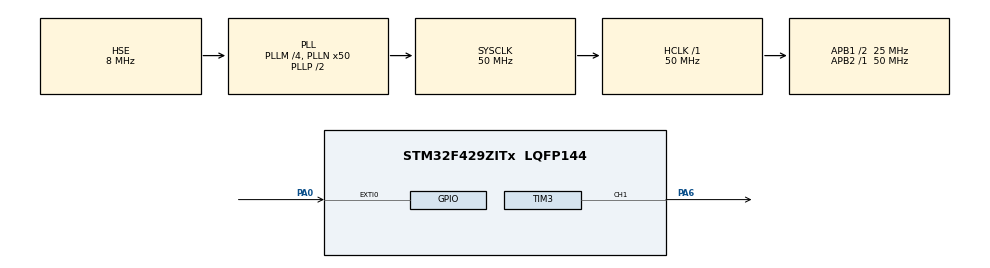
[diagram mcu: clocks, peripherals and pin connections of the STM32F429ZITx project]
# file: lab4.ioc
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Mcu.Family=STM32F4
Mcu.Name=STM32F429ZITx
Mcu.Package=LQFP144
NVIC.EXTI0_IRQn=true\:0\:0\:false\:false\:true\:true\:true\:true
NVIC.PriorityGroup=NVIC_PRIORITYGROUP_4
PA0/WKUP.GPIO_ModeDefaultEXTI=GPIO_MODE_IT_RISING
PA0/WKUP.Signal=GPXTI0
PA13.Mode=Serial_Wire
PA13.Signal=SYS_JTMS-SWDIO
PA14.Mode=Serial_Wire
PA14.Signal=SYS_JTCK-SWCLK
PA6.Signal=S_TIM3_CH1
PH0/OSC_IN.Mode=HSE-External-Oscillator
PH0/OSC_IN.Signal=RCC_OSC_IN
PH1/OSC_OUT.Mode=HSE-External-Oscillator
PH1/OSC_OUT.Signal=RCC_OSC_OUT
ProjectManager.HeapSize=0x200
ProjectManager.StackSize=0x400
ProjectManager.TargetToolchain=STM32CubeIDE
RCC.48MHZClocksFreq_Value=25000000
RCC.AHBFreq_Value=50000000
RCC.APB1CLKDivider=RCC_HCLK_DIV2
RCC.APB1Freq_Value=25000000
RCC.APB1TimFreq_Value=50000000
RCC.APB2Freq_Value=50000000
RCC.APB2TimFreq_Value=50000000
RCC.CortexFreq_Value=50000000
RCC.HCLKFreq_Value=50000000
RCC.HSE_VALUE=8000000
RCC.HSI_VALUE=16000000
RCC.LSE_VALUE=32768
RCC.PLLM=4
RCC.PLLN=50
RCC.PLLSourceVirtual=RCC_PLLSOURCE_HSE
RCC.SYSCLKFreq_VALUE=50000000
RCC.SYSCLKSource=RCC_SYSCLKSOURCE_PLLCLK
RCC.VCOOutputFreq_Value=100000000
SH.S_TIM3_CH1.0=TIM3_CH1,PWM Generation1 CH1
TIM3.Channel-PWM\ Generation1\ CH1=TIM_CHANNEL_1
TIM3.Period=499
TIM3.Prescaler=0
VP_TIM3_VS_ClockSourceINT.Mode=Internal
board=custom

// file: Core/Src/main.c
/* USER CODE BEGIN Header */
/**
  ******************************************************************************
  * @file           : main.c
  * @brief          : Main program body
  ******************************************************************************
  * @attention
  *
  * Copyright (c) 2024 STMicroelectronics.
  * All rights reserved.
  *
  * This software is licensed under terms that can be found in the LICENSE file
  * in the root directory of this software component.
  * If no LICENSE file comes with this software, it is provided AS-IS.
  *
  ******************************************************************************
  */
/* USER CODE END Header */
#include "main.h"

 TIM_HandleTypeDef htim3;

void SystemClock_Config(void);
static void MX_GPIO_Init(void);
static void MX_TIM3_Init(void);

double calculateSysTickOverflowPeriod(uint32_t);
/* USER CODE BEGIN PFP */
//void setPWM(uint16_t pwm_value);
/* USER CODE END PFP */

/* USER CODE BEGIN 0 */
const uint32_t sysclk = 50000000;

int16_t pwm_value = 0;
int8_t step = 100;
const uint16_t period = 500;
char button_flag = 0;
/* USER CODE END 0 */

int main(void)
{

  /* MCU Configuration--------------------------------------------------------*/

  /* Reset of all peripherals, Initializes the Flash interface and the Systick. */
  HAL_Init();

  /* Configure the system clock */
  SystemClock_Config();

  /* Initialize all configured peripherals */
  MX_GPIO_Init();
  MX_TIM3_Init();
  /* USER CODE BEGIN 2 */
  EXTI->IMR |= 1;
  EXTI->EMR |= 1;
  EXTI->RTSR |= 1;

  HAL_TIM_PWM_Start(&htim3, TIM_CHANNEL_1);
  TIM3->CCR1 = period;

  double sysTickOverflowPeriod = calculateSysTickOverflowPeriod(sysclk);
//  TIM3->CCR1 = (int) period / 2;
  /* USER CODE END 2 */

  /* Infinite loop */
  while (1)
  {

    /* USER CODE BEGIN 3 */
	  if(button_flag){
		  button_flag = 0;
		  if(pwm_value + step > period){
			  step = -step;
		  } else if (pwm_value + step < 0){
			  step = -step;
		  }
		  pwm_value += step;
		  htim3.Instance->CCR1 = pwm_value;
	  }
  }
  /* USER CODE END 3 */
}

void SystemClock_Config(void)
{
  RCC_OscInitTypeDef RCC_OscInitStruct = {0};
  RCC_ClkInitTypeDef RCC_ClkInitStruct = {0};

  /** Configure the main internal regulator output voltage
  */
  __HAL_RCC_PWR_CLK_ENABLE();
  __HAL_PWR_VOLTAGESCALING_CONFIG(PWR_REGULATOR_VOLTAGE_SCALE3);

  /** Initializes the RCC Oscillators according to the specified parameters
  * in the RCC_OscInitTypeDef structure.
  */
  RCC_OscInitStruct.OscillatorType = RCC_OSCILLATORTYPE_HSE;
  RCC_OscInitStruct.HSEState = RCC_HSE_ON;
  RCC_OscInitStruct.PLL.PLLState = RCC_PLL_ON;
  RCC_OscInitStruct.PLL.PLLSource = RCC_PLLSOURCE_HSE;
  RCC_OscInitStruct.PLL.PLLM = 4;
  RCC_OscInitStruct.PLL.PLLN = 50;
  RCC_OscInitStruct.PLL.PLLP = RCC_PLLP_DIV2;
  RCC_OscInitStruct.PLL.PLLQ = 4;
  if (HAL_RCC_OscConfig(&RCC_OscInitStruct) != HAL_OK)
  {
    Error_Handler();
  }

  /** Initializes the CPU, AHB and APB buses clocks
  */
  RCC_ClkInitStruct.ClockType = RCC_CLOCKTYPE_HCLK|RCC_CLOCKTYPE_SYSCLK
                              |RCC_CLOCKTYPE_PCLK1|RCC_CLOCKTYPE_PCLK2;
  RCC_ClkInitStruct.SYSCLKSource = RCC_SYSCLKSOURCE_PLLCLK;
  RCC_ClkInitStruct.AHBCLKDivider = RCC_SYSCLK_DIV1;
  RCC_ClkInitStruct.APB1CLKDivider = RCC_HCLK_DIV2;
  RCC_ClkInitStruct.APB2CLKDivider = RCC_HCLK_DIV1;

  if (HAL_RCC_ClockConfig(&RCC_ClkInitStruct, FLASH_LATENCY_1) != HAL_OK)
  {
    Error_Handler();
  }
}

static void MX_TIM3_Init(void)
{

  TIM_ClockConfigTypeDef sClockSourceConfig = {0};
  TIM_MasterConfigTypeDef sMasterConfig = {0};
  TIM_OC_InitTypeDef sConfigOC = {0};

  htim3.Instance = TIM3;
  htim3.Init.Prescaler = 0;
  htim3.Init.CounterMode = TIM_COUNTERMODE_UP;
  htim3.Init.Period = 499;
  htim3.Init.ClockDivision = TIM_CLOCKDIVISION_DIV1;
  htim3.Init.AutoReloadPreload = TIM_AUTORELOAD_PRELOAD_DISABLE;
  if (HAL_TIM_Base_Init(&htim3) != HAL_OK)
  {
    Error_Handler();
  }
  sClockSourceConfig.ClockSource = TIM_CLOCKSOURCE_INTERNAL;
  if (HAL_TIM_ConfigClockSource(&htim3, &sClockSourceConfig) != HAL_OK)
  {
    Error_Handler();
  }
  if (HAL_TIM_PWM_Init(&htim3) != HAL_OK)
  {
    Error_Handler();
  }
  sMasterConfig.MasterOutputTrigger = TIM_TRGO_RESET;
  sMasterConfig.MasterSlaveMode = TIM_MASTERSLAVEMODE_DISABLE;
  if (HAL_TIMEx_MasterConfigSynchronization(&htim3, &sMasterConfig) != HAL_OK)
  {
    Error_Handler();
  }
  sConfigOC.OCMode = TIM_OCMODE_PWM1;
  sConfigOC.Pulse = 0;
  sConfigOC.OCPolarity = TIM_OCPOLARITY_HIGH;
  sConfigOC.OCFastMode = TIM_OCFAST_DISABLE;
  if (HAL_TIM_PWM_ConfigChannel(&htim3, &sConfigOC, TIM_CHANNEL_1) != HAL_OK)
  {
    Error_Handler();
  }
  HAL_TIM_MspPostInit(&htim3);

}

static void MX_GPIO_Init(void)
{
  GPIO_InitTypeDef GPIO_InitStruct = {0};

  /* GPIO Ports Clock Enable */
  __HAL_RCC_GPIOH_CLK_ENABLE();
  __HAL_RCC_GPIOA_CLK_ENABLE();

  /*Configure GPIO pin : PA0 */
  GPIO_InitStruct.Pin = GPIO_PIN_0;
  GPIO_InitStruct.Mode = GPIO_MODE_IT_RISING;
  GPIO_InitStruct.Pull = GPIO_NOPULL;
  HAL_GPIO_Init(GPIOA, &GPIO_InitStruct);

  /* EXTI interrupt init*/
  HAL_NVIC_SetPriority(EXTI0_IRQn, 0, 0);
  HAL_NVIC_EnableIRQ(EXTI0_IRQn);

}

/* USER CODE BEGIN 4 */
double calculateSysTickOverflowPeriod(uint32_t sys_clk) {
    uint32_t reload_value = SysTick->LOAD + 1; // Значение перезагрузки регистра
    double tick_time = 1.0 / sys_clk;          // Время одного тика таймера
    return (double)reload_value * tick_time;   // Период переполнения
}

void EXTI0_IRQHandler(void)
{
  /* USER CODE BEGIN EXTI0_IRQn 0 */
	button_flag = 1;
  /* USER CODE END EXTI0_IRQn 0 */
  HAL_GPIO_EXTI_IRQHandler(GPIO_PIN_0);
  /* USER CODE BEGIN EXTI0_IRQn 1 */

  /* USER CODE END EXTI0_IRQn 1 */
}
/* USER CODE END 4 */

void Error_Handler(void)
{
  __disable_irq();
  while (1)
  {
  }
}
